# STM32U366xx register map
File version: 1.0
Registers are 32-bit, read-write, reset 0x0 unless marked. A register's access mark holds for its fields unless they carry their own. Offsets are from the block's base; [hi:lo] are bit positions; {n}, {i} and the like mark numbered series; 'fields as' and 'values as' point back to an identical list.

## GTZC_MPCBB1
Base 0x40032C00
Same registers: GTZC_MPCBB2 0x40033000
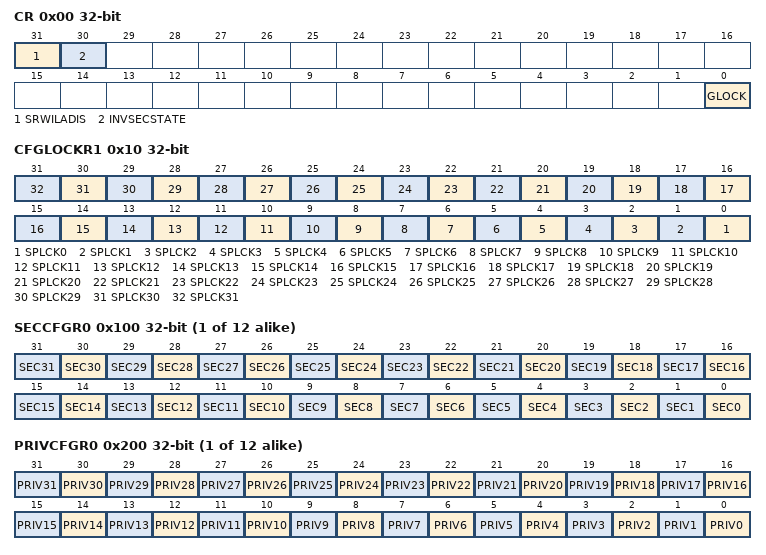
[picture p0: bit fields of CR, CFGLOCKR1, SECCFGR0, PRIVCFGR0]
0x00 CR — MPCBBx control register
  [31] SRWILADIS, [30] INVSECSTATE, [0] GLOCK
0x10 CFGLOCKR1 — MPCBBx Configuration lock register
  [n] SPLCK{n} (n=0..31)
{0x100+4i} SECCFGR{i} (i=0..11) — MPCBBx security configuration registers
  [n] SEC{n} (n=0..31)
{0x200+4i} PRIVCFGR{i} (i=0..11) — MPCBBx privilege configuration registers
  [n] PRIV{n} (n=0..31)

## SYSCFG — System configuration controller
Base 0x40040400
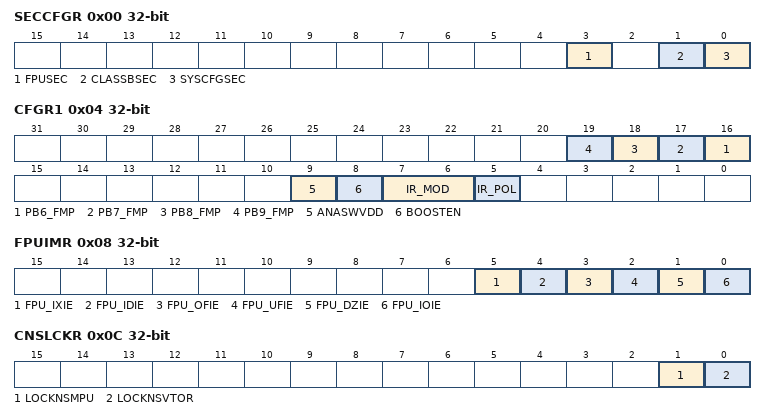
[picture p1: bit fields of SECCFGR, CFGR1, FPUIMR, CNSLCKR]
0x00 SECCFGR — SYSCFG secure configuration register
  [3] FPUSEC — FPU SYSCFG security enable
  [1] CLASSBSEC — ClassB SYSCFG security enable
  [0] SYSCFGSEC — SYSCFG clock control security enable
0x04 CFGR1 — SYSCFG configuration register 1
  [n+10] PB{n}_FMP (n=6..9) — PB{n} Fast mode plus
  [9] ANASWVDD — GPIO analog switch control voltage selection
  [8] BOOSTEN — I/O analog switch voltage booster enable
  [7:6] IR_MOD — IR Modulation Envelope signal selection
  [5] IR_POL — IR output polarity selection
0x08 FPUIMR — SYSCFG FPU interrupt mask register
  [5] FPU_IXIE — Floating point unit interrupt enable bit - inexact
  [4] FPU_IDIE — Floating point unit interrupt enable bit - input denormal
  [3] FPU_OFIE — Floating point unit interrupt enable bit - overflow
  [2] FPU_UFIE — Floating point unit interrupt enable bit - underflow
  [1] FPU_DZIE — Floating point unit interrupt enable bit - divide-by-zero
  [0] FPU_IOIE — Floating point unit interrupt enable bit - invalid operation
0x0C CNSLCKR — SYSCFG CPU non-secure lock register
  [1] LOCKNSMPU — Disable Non-Secure MPU registers writes by SW or debug agent
  [0] LOCKNSVTOR — Disable VTOR_NS register writes by SW or debug agent
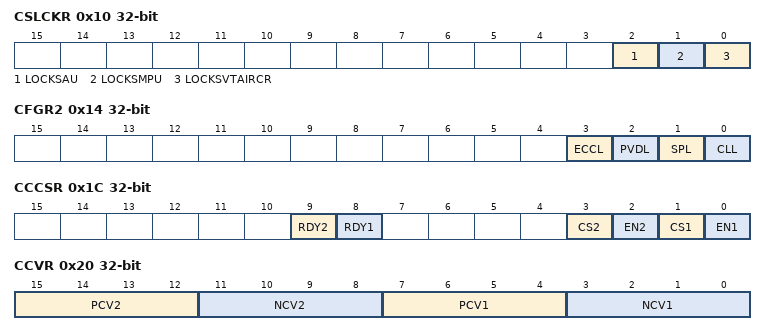
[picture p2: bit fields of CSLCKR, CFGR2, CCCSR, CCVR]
0x10 CSLCKR — SYSCFG CPU secure lock register
  [2] LOCKSAU — Disable changes to SAU registers
  [1] LOCKSMPU — Disable changes to the secure MPU registers writes by SW or debug agent
  [0] LOCKSVTAIRCR — Disable changes to the secure vector table address, handling of system faults
0x14 CFGR2 — SYSCFG configuration register 2
  [3] ECCL — ECC Lock
  [2] PVDL — PVD Lock
  [1] SPL — SRAM parity Lock
  [0] CLL — Core Lockup Lock
0x1C CCCSR — SYSCFG Conpensaion Cell Control&Status register
  [9] RDY2 — VDDIO compensation cell ready flag
  [8] RDY1 — VDD compensation cell ready flag
  [3] CS2 — Code selection for VDDIO power rail
  [2] EN2 — Enable compensation cell for VDDIO power rail
  [1] CS1 — Code selection for VDD power rail
  [0] EN1 — Enable compensation cell for VDD power rail
0x20 CCVR — SYSCFG Conpensaion Cell value register
  [15:12] PCV2 — PMOS compensation value for VDDIO Power Rail
  [11:8] NCV2 — NMOS compensation value for VDDIO Power Rail
  [7:4] PCV1 — PMOS compensation value for VDD Power Rail
  [3:0] NCV1 — NMOS compensation value for VDD Power Rail
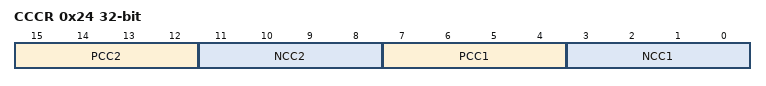
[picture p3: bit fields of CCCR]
0x24 CCCR — SYSCFG Conpensaion Cell Code register
  [15:12] PCC2 — PMOS compensation code for VDDIO Power Rail
  [11:8] NCC2 — NMOS compensation code for VDDIO Power Rail
  [7:4] PCC1 — PMOS compensation code for VDD Power Rail
  [3:0] NCC1 — NMOS compensation code for VDD Power Rail
0x2C RSSCMDR — SYSCFG RSS command mode register
  [15:0] RSSCMD — RSS commands

## COMP12_COMMON
Base 0x40045400
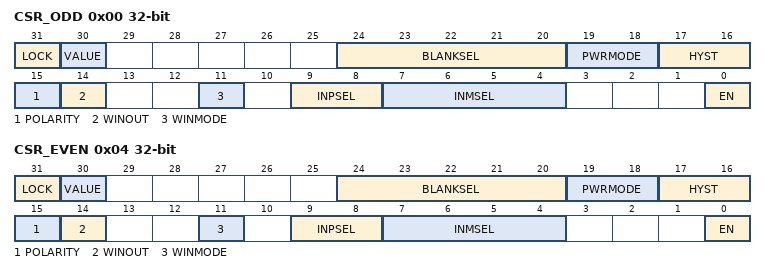
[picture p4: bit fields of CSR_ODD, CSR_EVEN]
0x00 CSR_ODD — COMP control and status register located in register of comparator instance odd, used for bits common to several COMP instances
  [31] LOCK — COMPx Lock Bit
  [30] VALUE — COMPx enable bit
  [24:20] BLANKSEL — COMPx blanking source selection bits
    0=NONE (Comparator output without blanking); 1=TIM1_OC5 (Comparator output blanking source TIM1 OC5 for COMP1 Instance); 2=TIM2_OC3 (Comparator output blanking source TIM2 OC3 for COMP1 Instance); 4=TIM3_OC3 (Comparator output blanking source TIM3 OC3 for COMP1 Instance)
  [19:18] PWRMODE — COMPx Power Mode of the comparator
    0=HIGHSPEED (COMP power mode to high speed); 1=MEDIUMSPEED (COMP power mode to medium speed); 3=ULTRALOWPOWER (COMP power mode to ultra-low power)
  [17:16] HYST — COMPx hysteresis selection bits
    0=NONE (No hysteresis); 1=LOW (Hysteresis level low); 2=MEDIUM (Hysteresis level medium); 3=HIGH (Hysteresis level high)
  [15] POLARITY — COMPx polarity selection bit
    0=NONINVERTED (COMP output polarity is not inverted: comparator output is high when the plus (non-inverting) input is at a higher voltage than the minus (inverting) input); 1=INVERTED (COMP output polarity is inverted: comparator output is low when the plus (non-inverting) input is at a lower voltage than the minus (inverting) input)
  [14] WINOUT — COMPx polarity selection bit
  [11] WINMODE — COMPx Windows mode selection bit
  [9:8] INPSEL — COMPx input plus selection bit
    0=IO1 (Comparator input plus connected to IO1 (pin PC5 for COMP1, pin PB4 for COMP2)); 1=IO2 (Comparator input plus connected to IO2 (pin PB2 for COMP1, pin PB6 for COMP2)); 2=IO3 (Comparator input plus connected to IO3 (pin PA2 for COMP1)); 3=IO4 (Comparator input plus connected to IO4 (pin PA3 for COMP1))
  [7:4] INMSEL — COMPx input minus selection bit
    0=MINUS_1_4VREFINT (Comparator input minus connected to 1/4 VrefInt); 1=MINUS_1_2VREFINT (Comparator input minus connected to 1/2 VrefInt); 2=MINUS_3_4VREFINT (Comparator input minus connected to 3/4 VrefInt); 3=VREFINT (Comparator input minus connected to VrefInt); 4=DAC1_CH1 (Comparator input minus connected to DAC1 channel 1 (DAC_OUT1)); 5=DAC1_CH2 (Comparator input minus connected to DAC1 channel 2 (DAC_OUT2)); 6=IO1 (Comparator input minus connected to IO1 (pin PB1 for COMP1, pin PB7 for COMP2)); 7=IO2 (Comparator input minus connected to IO2 (pin PC4 for COMP1, pin PB3 for COMP2))
  [0] EN — COMPx enable bit
0x04 CSR_EVEN — COMP control and status register located in register of comparator instance even, used for bits common to several COMP instances
  fields as CSR_ODD
